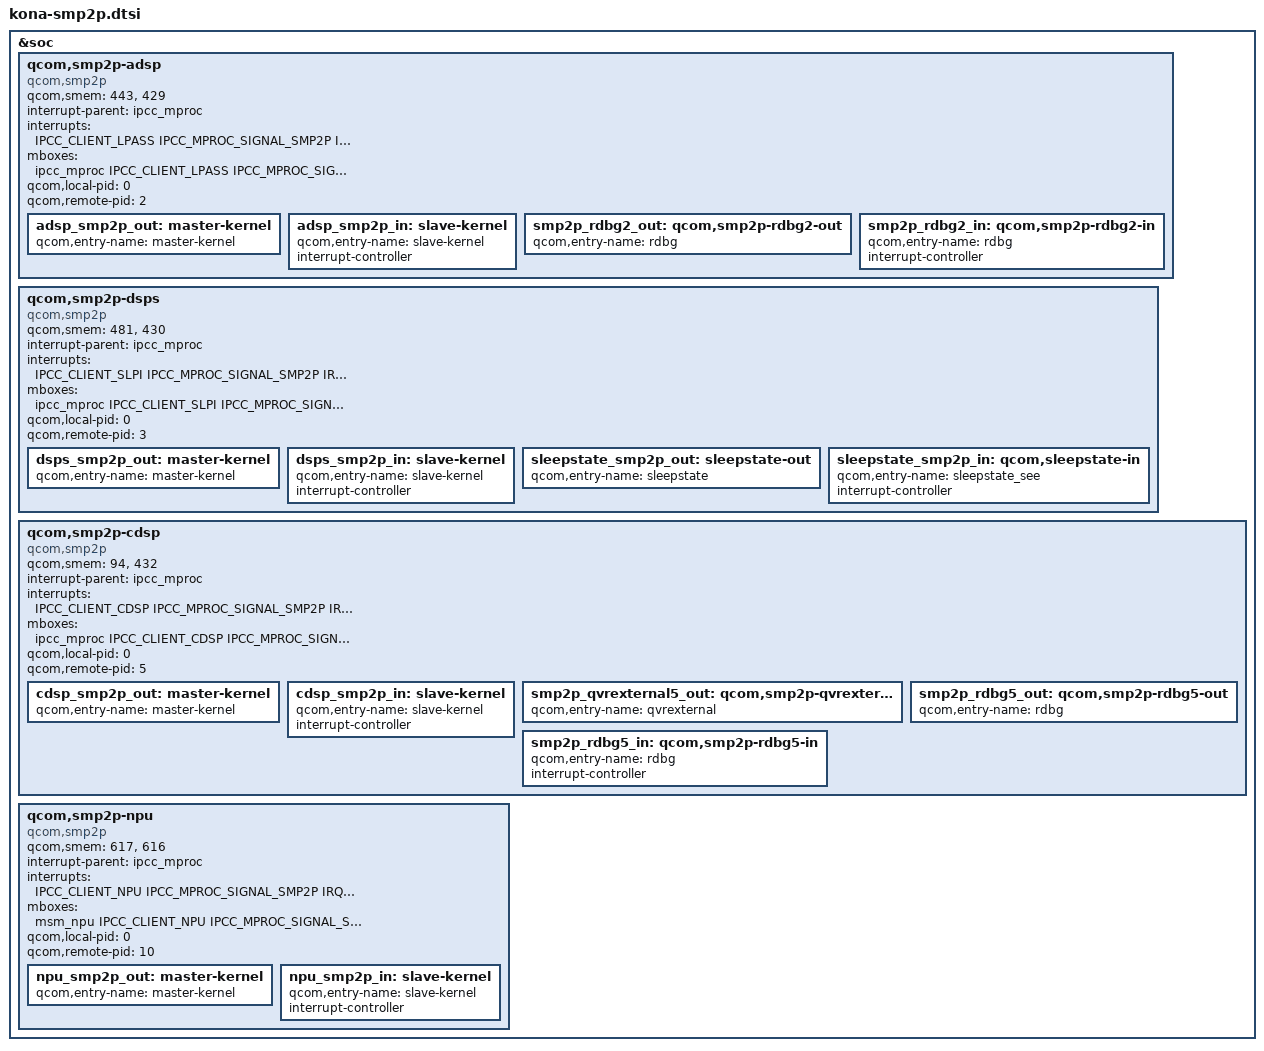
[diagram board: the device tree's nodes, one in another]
#include <dt-bindings/interrupt-controller/arm-gic.h>
#include <dt-bindings/soc/qcom,ipcc.h>

&soc {

	qcom,smp2p-adsp {
		#address-cells = <0>;
		#size-cells = <0>;
		compatible = "qcom,smp2p";
		qcom,smem = <443>, <429>;
		interrupt-parent = <&ipcc_mproc>;
		interrupts = <IPCC_CLIENT_LPASS IPCC_MPROC_SIGNAL_SMP2P
			      IRQ_TYPE_EDGE_RISING>;
		mboxes = <&ipcc_mproc IPCC_CLIENT_LPASS
			  IPCC_MPROC_SIGNAL_SMP2P>;
		qcom,local-pid = <0>;
		qcom,remote-pid = <2>;

		adsp_smp2p_out: master-kernel {
			#address-cells = <0>;
			qcom,entry-name = "master-kernel";
			#qcom,smem-state-cells = <1>;
		};

		adsp_smp2p_in: slave-kernel {
			#address-cells = <0>;
			qcom,entry-name = "slave-kernel";
			interrupt-controller;
			#interrupt-cells = <2>;
		};

		smp2p_rdbg2_out: qcom,smp2p-rdbg2-out {
			#address-cells = <0>;
			qcom,entry-name = "rdbg";
			#qcom,smem-state-cells = <1>;
		};

		smp2p_rdbg2_in: qcom,smp2p-rdbg2-in {
			#address-cells = <0>;
			qcom,entry-name = "rdbg";
			interrupt-controller;
			#interrupt-cells = <2>;
		};
	};

	qcom,smp2p-dsps {
		#address-cells = <0>;
		#size-cells = <0>;
		compatible = "qcom,smp2p";
		qcom,smem = <481>, <430>;
		interrupt-parent = <&ipcc_mproc>;
		interrupts = <IPCC_CLIENT_SLPI IPCC_MPROC_SIGNAL_SMP2P
			      IRQ_TYPE_EDGE_RISING>;
		mboxes = <&ipcc_mproc IPCC_CLIENT_SLPI IPCC_MPROC_SIGNAL_SMP2P>;
		qcom,local-pid = <0>;
		qcom,remote-pid = <3>;

		dsps_smp2p_out: master-kernel {
			#address-cells = <0>;
			qcom,entry-name = "master-kernel";
			#qcom,smem-state-cells = <1>;
		};

		dsps_smp2p_in: slave-kernel {
			#address-cells = <0>;
			qcom,entry-name = "slave-kernel";
			interrupt-controller;
			#interrupt-cells = <2>;
		};

		sleepstate_smp2p_out: sleepstate-out {
			#address-cells = <0>;
			qcom,entry-name = "sleepstate";
			#qcom,smem-state-cells = <1>;
		};

		sleepstate_smp2p_in: qcom,sleepstate-in {
			#address-cells = <0>;
			qcom,entry-name = "sleepstate_see";
			interrupt-controller;
			#interrupt-cells = <2>;
		};
	};

	qcom,smp2p-cdsp {
		#address-cells = <0>;
		#size-cells = <0>;
		compatible = "qcom,smp2p";
		qcom,smem = <94>, <432>;
		interrupt-parent = <&ipcc_mproc>;
		interrupts = <IPCC_CLIENT_CDSP IPCC_MPROC_SIGNAL_SMP2P
			      IRQ_TYPE_EDGE_RISING>;
		mboxes = <&ipcc_mproc IPCC_CLIENT_CDSP IPCC_MPROC_SIGNAL_SMP2P>;
		qcom,local-pid = <0>;
		qcom,remote-pid = <5>;

		cdsp_smp2p_out: master-kernel {
			#address-cells = <0>;
			qcom,entry-name = "master-kernel";
			#qcom,smem-state-cells = <1>;
		};

		cdsp_smp2p_in: slave-kernel {
			#address-cells = <0>;
			qcom,entry-name = "slave-kernel";
			interrupt-controller;
			#interrupt-cells = <2>;
		};

		smp2p_qvrexternal5_out: qcom,smp2p-qvrexternal5-out {
			#address-cells = <0>;
			qcom,entry-name = "qvrexternal";
			#qcom,smem-state-cells = <1>;
		};

		smp2p_rdbg5_out: qcom,smp2p-rdbg5-out {
			#address-cells = <0>;
			qcom,entry-name = "rdbg";
			#qcom,smem-state-cells = <1>;
		};

		smp2p_rdbg5_in: qcom,smp2p-rdbg5-in {
			#address-cells = <0>;
			qcom,entry-name = "rdbg";
			interrupt-controller;
			#interrupt-cells = <2>;
		};
	};

	qcom,smp2p-npu {
		#address-cells = <0>;
		#size-cells = <0>;
		compatible = "qcom,smp2p";
		qcom,smem = <617>, <616>;
		interrupt-parent = <&ipcc_mproc>;
		interrupts = <IPCC_CLIENT_NPU IPCC_MPROC_SIGNAL_SMP2P
			      IRQ_TYPE_EDGE_RISING>;
		mboxes = <&msm_npu IPCC_CLIENT_NPU IPCC_MPROC_SIGNAL_SMP2P>;
		qcom,local-pid = <0>;
		qcom,remote-pid = <10>;

		npu_smp2p_out: master-kernel {
			#address-cells = <0>;
			qcom,entry-name = "master-kernel";
			#qcom,smem-state-cells = <1>;
		};

		npu_smp2p_in: slave-kernel {
			#address-cells = <0>;
			qcom,entry-name = "slave-kernel";
			interrupt-controller;
			#interrupt-cells = <2>;
		};
	};
};

